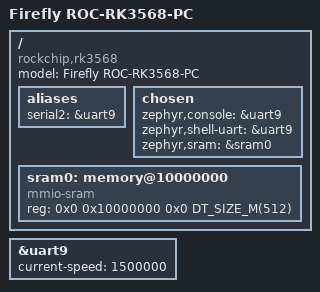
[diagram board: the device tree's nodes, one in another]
/*
 * Copyright 2022 HNU-ESNL
 * Copyright 2022 openEuler SIG-Zephyr
 * SPDX-License-Identifier: Apache-2.0
 */

/dts-v1/;

#include <arm64/rockchip/rk3568.dtsi>
#include <common/mem.h>

/ {
	model = "Firefly ROC-RK3568-PC";
	compatible = "rockchip,rk3568";

	aliases {
		serial2 = &uart9;
	};

	chosen {
		zephyr,console = &uart9;
		zephyr,shell-uart = &uart9;
		zephyr,sram = &sram0;
	};

	sram0: memory@10000000 {
		device_type = "memory";
		compatible = "mmio-sram";
		reg = <0x0 0x10000000 0x0 DT_SIZE_M(512)>;
	};

};

&uart9 {
	status = "okay";
	current-speed = <1500000>;
};
